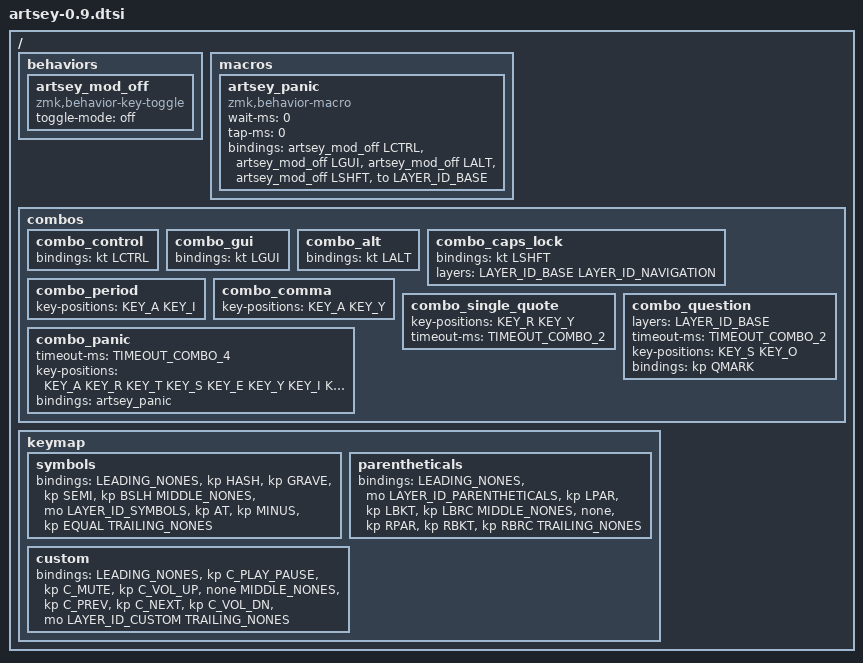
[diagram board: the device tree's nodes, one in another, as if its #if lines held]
/*
 * ARTSEY 0.9 beta port. See docs/artsey-0.9.md for sources and differences.
 * SPDX-License-Identifier: MIT
 */

#if defined ARDUX_BIG || defined ARDUX_COLEMAK
#error "ARTSEY_09 supports only the standard eight-key ARTSEY layout"
#endif

/ {
	behaviors {
		artsey_mod_off: artsey_mod_off {
			compatible = "zmk,behavior-key-toggle";
			#binding-cells = <1>;
			toggle-mode = "off";
		};
	};

	macros {
		artsey_panic: artsey_panic {
			compatible = "zmk,behavior-macro";
			#binding-cells = <0>;
			wait-ms = <0>;
			tap-ms = <0>;
			bindings = <&artsey_mod_off LCTRL &artsey_mod_off LGUI
				&artsey_mod_off LALT &artsey_mod_off LSHFT
				&to LAYER_ID_BASE>;
		};
	};

	combos {
		// Control, Command, and Option latch until the same chord is tapped again.
		combo_control { bindings = <&kt LCTRL>; };
		combo_gui { bindings = <&kt LGUI>; };
		combo_alt { bindings = <&kt LALT>; };
		/delete-node/ combo_shift_lock;
		combo_caps_lock { bindings = <&kt LSHFT>; layers = <LAYER_ID_BASE LAYER_ID_NAVIGATION>; };

		combo_period { key-positions = <KEY_A KEY_I>; };
		combo_comma { key-positions = <KEY_A KEY_Y>; };
		combo_single_quote { key-positions = <KEY_R KEY_Y>; timeout-ms = <TIMEOUT_COMBO_2>; };
		combo_question {
			layers = <LAYER_ID_BASE>;
			timeout-ms = <TIMEOUT_COMBO_2>;
			key-positions = <KEY_S KEY_O>;
			bindings = <&kp QMARK>;
		};
		combo_panic {
			timeout-ms = <TIMEOUT_COMBO_4>;
			key-positions = <KEY_A KEY_R KEY_T KEY_S KEY_E KEY_Y KEY_I KEY_O>;
			bindings = <&artsey_panic>;
		};
	};

	keymap {
		symbols {
			bindings = <
				LEADING_NONES
#if defined ARDUX_RIGHT
				&kp HASH &kp GRAVE &kp SEMI &kp BSLH
				MIDDLE_NONES
				&mo LAYER_ID_SYMBOLS &kp AT &kp MINUS &kp EQUAL
#else
				&kp BSLH &kp SEMI &kp GRAVE &kp HASH
				MIDDLE_NONES
				&kp EQUAL &kp MINUS &kp AT &mo LAYER_ID_SYMBOLS
#endif
				TRAILING_NONES
			>;
		};
		parentheticals {
			bindings = <
				LEADING_NONES
#if defined ARDUX_RIGHT
				&mo LAYER_ID_PARENTHETICALS &kp LPAR &kp LBKT &kp LBRC
				MIDDLE_NONES
				&none &kp RPAR &kp RBKT &kp RBRC
#else
				&kp LBRC &kp LBKT &kp LPAR &mo LAYER_ID_PARENTHETICALS
				MIDDLE_NONES
				&kp RBRC &kp RBKT &kp RPAR &none
#endif
				TRAILING_NONES
			>;
		};
		custom {
			bindings = <
				LEADING_NONES
#if defined ARDUX_RIGHT
				&kp C_PLAY_PAUSE &kp C_MUTE &kp C_VOL_UP &none
				MIDDLE_NONES
				&kp C_PREV &kp C_NEXT &kp C_VOL_DN &mo LAYER_ID_CUSTOM
#else
				&none &kp C_VOL_UP &kp C_MUTE &kp C_PLAY_PAUSE
				MIDDLE_NONES
				&mo LAYER_ID_CUSTOM &kp C_VOL_DN &kp C_PREV &kp C_NEXT
#endif
				TRAILING_NONES
			>;
		};
	};
};
